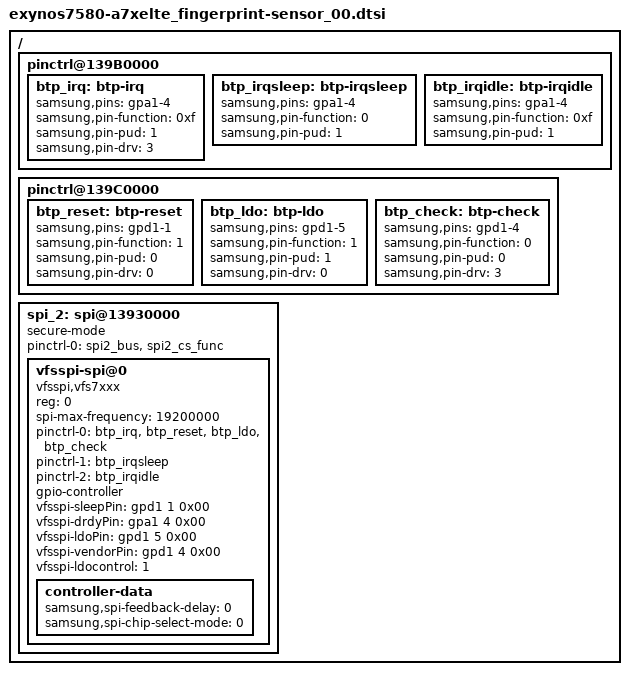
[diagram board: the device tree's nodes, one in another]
/*
 * Copyright (c) 2012-2013, The Linux Foundation. All rights reserved.
 *
 * This program is free software; you can redistribute it and/or modify
 * it under the terms of the GNU General Public License version 2 and
 * only version 2 as published by the Free Software Foundation.
 *
 * This program is distributed in the hope that it will be useful,
 * but WITHOUT ANY WARRANTY; without even the implied warranty of
 * MERCHANTABILITY or FITNESS FOR A PARTICULAR PURPOSE.  See the
 * GNU General Public License for more details.
 */

/ {
	pinctrl@139B0000 {
		btp_irq: btp-irq {
			samsung,pins = "gpa1-4";
			samsung,pin-function = <0xf>;
			samsung,pin-pud = <1>;
			samsung,pin-drv = <3>;
		};
		btp_irqsleep: btp-irqsleep {
			samsung,pins = "gpa1-4";
		    samsung,pin-function = <0>;
			samsung,pin-pud = <1>;
		};
		btp_irqidle: btp-irqidle {
			samsung,pins = "gpa1-4";
			samsung,pin-function = <0xf>;
			samsung,pin-pud = <1>;
		};
	};
	pinctrl@139C0000 {
		btp_reset: btp-reset {
			samsung,pins = "gpd1-1";
			samsung,pin-function = <1>;
			samsung,pin-pud = <0>;
			samsung,pin-drv = <0>;
		};
		btp_ldo: btp-ldo {
			samsung,pins = "gpd1-5";
			samsung,pin-function = <1>;
			samsung,pin-pud = <1>;
			samsung,pin-drv = <0>;
		};
		btp_check: btp-check {
			samsung,pins = "gpd1-4";
			samsung,pin-function = <0>;
			samsung,pin-pud = <0>;
			samsung,pin-drv = <3>;
		};
	};

	spi_2: spi@13930000 {
		status = "okay";
		secure-mode;
		/delete-property/ dma-mode;
		/delete-property/ dmas;
		/delete-property/ dma-names;
		#address-cells = <1>;
		#size-cells = <0>;
		pinctrl-names = "default";
		pinctrl-0 = <&spi2_bus &spi2_cs_func>;

		vfsspi-spi@0 {
			compatible = "vfsspi,vfs7xxx";
			reg = <0>;
			spi-max-frequency = <19200000>;
			pinctrl-names = "default", "sleep", "idle";
			pinctrl-0 = <&btp_irq &btp_reset &btp_ldo &btp_check>;
			pinctrl-1 = <&btp_irqsleep>;
			pinctrl-2 = <&btp_irqidle>;

			gpio-controller;
			#gpio-cells = <2>;

			vfsspi-sleepPin = <&gpd1 1 0x00>;
			vfsspi-drdyPin = <&gpa1 4 0x00>;
			vfsspi-ldoPin = <&gpd1 5 0x00>;
			vfsspi-vendorPin = <&gpd1 4 0x00>;
			vfsspi-ldocontrol = <1>;
			controller-data {
				samsung,spi-feedback-delay = <0>;
				samsung,spi-chip-select-mode = <0>;
			};
		};
	};
};

